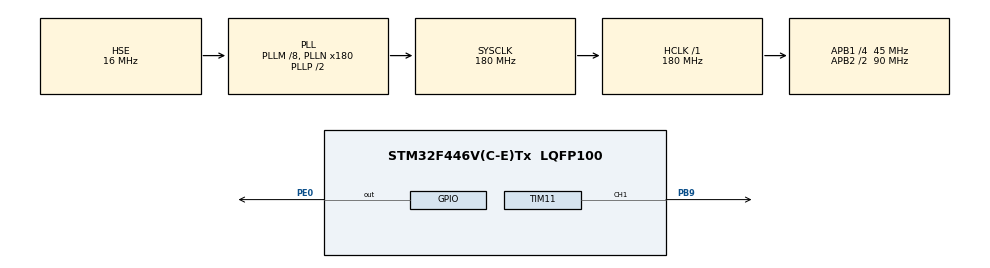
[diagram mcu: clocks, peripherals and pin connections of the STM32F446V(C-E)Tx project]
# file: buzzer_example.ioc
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Mcu.Family=STM32F4
RCC.PLLSourceVirtual=RCC_PLLSOURCE_HSE
PH0-OSC_IN.Signal=RCC_OSC_IN
RCC.CortexFreq_Value=180000000
TIM11.Prescaler=1
RCC.APB1CLKDivider=RCC_HCLK_DIV4
RCC.SYSCLKSource=RCC_SYSCLKSOURCE_PLLCLK
ProjectManager.StackSize=0x400
VP_TIM11_VS_ClockSourceINT.Mode=Enable_Timer
ProjectManager.TargetToolchain=EWARM V8.32
RCC.HCLKFreq_Value=180000000
RCC.APB2TimFreq_Value=180000000
RCC.USBFreq_Value=180000000
RCC.AHBFreq_Value=180000000
PH0-OSC_IN.Mode=HSE-External-Oscillator
RCC.HSE_VALUE=16000000
board=custom
RCC.VCOOutputFreq_Value=360000000
TIM11.Period=39130
RCC.APB2Freq_Value=90000000
PH1-OSC_OUT.Signal=RCC_OSC_OUT
PE0.Signal=GPIO_Output
Mcu.Name=STM32F446V(C-E)Tx
PH1-OSC_OUT.Mode=HSE-External-Oscillator
RCC.SYSCLKFreq_VALUE=180000000
PB9.Signal=S_TIM11_CH1
Mcu.Package=LQFP100
ProjectManager.HeapSize=0x200
NVIC.PriorityGroup=NVIC_PRIORITYGROUP_4
RCC.APB2CLKDivider=RCC_HCLK_DIV2
RCC.PLLM=8
RCC.PLLN=180
TIM11.Channel=TIM_CHANNEL_1
RCC.APB1TimFreq_Value=90000000
SH.S_TIM11_CH1.0=TIM11_CH1,PWM Generation1 CH1
RCC.APB1Freq_Value=45000000

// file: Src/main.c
/* USER CODE BEGIN Header */
/**
  ******************************************************************************
  * @file           : main.c
  * @brief          : Main program body
  ******************************************************************************
  * @attention
  *
  * <h2><center>&copy; Copyright (c) 2020 STMicroelectronics.
  * All rights reserved.</center></h2>
  *
  * This software component is licensed by ST under BSD 3-Clause license,
  * the "License"; You may not use this file except in compliance with the
  * License. You may obtain a copy of the License at:
  *                        opensource.org/licenses/BSD-3-Clause
  *
  ******************************************************************************
  */
/* USER CODE END Header */

#include "main.h"

/* USER CODE BEGIN Includes */
#include <stdbool.h>
/* USER CODE END Includes */

TIM_HandleTypeDef htim11;

void SystemClock_Config(void);
static void MX_GPIO_Init(void);
static void MX_TIM11_Init(void);

/* USER CODE BEGIN 0 */
bool toggle;
/* USER CODE END 0 */

int main(void)
{

  /* MCU Configuration--------------------------------------------------------*/

  /* Reset of all peripherals, Initializes the Flash interface and the Systick. */
  HAL_Init();

  /* Configure the system clock */
  SystemClock_Config();

  /* Initialize all configured peripherals */
  MX_GPIO_Init();
  MX_TIM11_Init();
  /* USER CODE BEGIN 2 */

  HAL_TIM_Base_Start(&htim11);
  HAL_TIM_PWM_Start(&htim11, TIM_CHANNEL_1);

  /* USER CODE END 2 */

  /* Infinite loop */
  /* USER CODE BEGIN WHILE */
  while (1)
  {
    if(toggle){
      htim11.Instance->CCR1 = htim11.Instance->ARR >> 1;
      HAL_GPIO_WritePin(GPIOE, GPIO_PIN_0, GPIO_PIN_SET);
    }else{
      htim11.Instance->CCR1 = 0;
      HAL_GPIO_WritePin(GPIOE, GPIO_PIN_0, GPIO_PIN_RESET);
    }

    toggle = !toggle;
    HAL_Delay(500);
    /* USER CODE END WHILE */

  }
}

void SystemClock_Config(void)
{
  RCC_OscInitTypeDef RCC_OscInitStruct = {0};
  RCC_ClkInitTypeDef RCC_ClkInitStruct = {0};

  /** Configure the main internal regulator output voltage
  */
  __HAL_RCC_PWR_CLK_ENABLE();
  __HAL_PWR_VOLTAGESCALING_CONFIG(PWR_REGULATOR_VOLTAGE_SCALE1);
  /** Initializes the CPU, AHB and APB busses clocks
  */
  RCC_OscInitStruct.OscillatorType = RCC_OSCILLATORTYPE_HSE;
  RCC_OscInitStruct.HSEState = RCC_HSE_ON;
  RCC_OscInitStruct.PLL.PLLState = RCC_PLL_ON;
  RCC_OscInitStruct.PLL.PLLSource = RCC_PLLSOURCE_HSE;
  RCC_OscInitStruct.PLL.PLLM = 8;
  RCC_OscInitStruct.PLL.PLLN = 180;
  RCC_OscInitStruct.PLL.PLLP = RCC_PLLP_DIV2;
  RCC_OscInitStruct.PLL.PLLQ = 2;
  RCC_OscInitStruct.PLL.PLLR = 2;
  if (HAL_RCC_OscConfig(&RCC_OscInitStruct) != HAL_OK)
  {
    Error_Handler();
  }
  /** Activate the Over-Drive mode
  */
  if (HAL_PWREx_EnableOverDrive() != HAL_OK)
  {
    Error_Handler();
  }
  /** Initializes the CPU, AHB and APB busses clocks
  */
  RCC_ClkInitStruct.ClockType = RCC_CLOCKTYPE_HCLK|RCC_CLOCKTYPE_SYSCLK
                              |RCC_CLOCKTYPE_PCLK1|RCC_CLOCKTYPE_PCLK2;
  RCC_ClkInitStruct.SYSCLKSource = RCC_SYSCLKSOURCE_PLLCLK;
  RCC_ClkInitStruct.AHBCLKDivider = RCC_SYSCLK_DIV1;
  RCC_ClkInitStruct.APB1CLKDivider = RCC_HCLK_DIV4;
  RCC_ClkInitStruct.APB2CLKDivider = RCC_HCLK_DIV2;

  if (HAL_RCC_ClockConfig(&RCC_ClkInitStruct, FLASH_LATENCY_5) != HAL_OK)
  {
    Error_Handler();
  }
}

static void MX_TIM11_Init(void)
{

  TIM_OC_InitTypeDef sConfigOC = {0};

  htim11.Instance = TIM11;
  htim11.Init.Prescaler = 1;
  htim11.Init.CounterMode = TIM_COUNTERMODE_UP;
  htim11.Init.Period = 39130;
  htim11.Init.ClockDivision = TIM_CLOCKDIVISION_DIV1;
  htim11.Init.AutoReloadPreload = TIM_AUTORELOAD_PRELOAD_DISABLE;
  if (HAL_TIM_Base_Init(&htim11) != HAL_OK)
  {
    Error_Handler();
  }
  if (HAL_TIM_PWM_Init(&htim11) != HAL_OK)
  {
    Error_Handler();
  }
  sConfigOC.OCMode = TIM_OCMODE_PWM1;
  sConfigOC.Pulse = 0;
  sConfigOC.OCPolarity = TIM_OCPOLARITY_HIGH;
  sConfigOC.OCFastMode = TIM_OCFAST_DISABLE;
  if (HAL_TIM_PWM_ConfigChannel(&htim11, &sConfigOC, TIM_CHANNEL_1) != HAL_OK)
  {
    Error_Handler();
  }
  HAL_TIM_MspPostInit(&htim11);

}

static void MX_GPIO_Init(void)
{
  GPIO_InitTypeDef GPIO_InitStruct = {0};

  /* GPIO Ports Clock Enable */
  __HAL_RCC_GPIOH_CLK_ENABLE();
  __HAL_RCC_GPIOB_CLK_ENABLE();
  __HAL_RCC_GPIOE_CLK_ENABLE();

  /*Configure GPIO pin Output Level */
  HAL_GPIO_WritePin(GPIOE, GPIO_PIN_0, GPIO_PIN_RESET);

  /*Configure GPIO pin : PE0 */
  GPIO_InitStruct.Pin = GPIO_PIN_0;
  GPIO_InitStruct.Mode = GPIO_MODE_OUTPUT_PP;
  GPIO_InitStruct.Pull = GPIO_NOPULL;
  GPIO_InitStruct.Speed = GPIO_SPEED_FREQ_LOW;
  HAL_GPIO_Init(GPIOE, &GPIO_InitStruct);

}

void Error_Handler(void)
{
}

/************************ (C) COPYRIGHT STMicroelectronics *****END OF FILE****/
